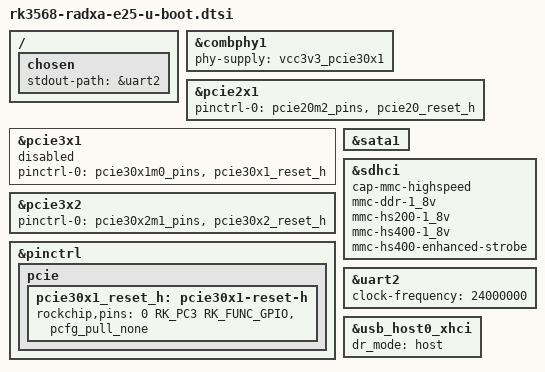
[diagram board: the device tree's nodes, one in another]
// SPDX-License-Identifier: GPL-2.0+

#include "rk356x-u-boot.dtsi"

/ {
	chosen {
		stdout-path = &uart2;
	};
};

&combphy1 {
	phy-supply = <&vcc3v3_pcie30x1>;
};

&pcie2x1 {
	pinctrl-0 = <&pcie20m2_pins &pcie20_reset_h>;
};

&pcie3x1 {
	pinctrl-0 = <&pcie30x1m0_pins &pcie30x1_reset_h>;
	/* May cause a sys freeze, disable for now */
	status = "disabled";
};

&pcie3x2 {
	pinctrl-0 = <&pcie30x2m1_pins &pcie30x2_reset_h>;
};

&pinctrl {
	pcie {
		pcie30x1_reset_h: pcie30x1-reset-h {
			rockchip,pins = <0 RK_PC3 RK_FUNC_GPIO &pcfg_pull_none>;
		};
	};
};

&sata1 {
	status = "okay";
};

&sdhci {
	cap-mmc-highspeed;
	mmc-ddr-1_8v;
	mmc-hs200-1_8v;
	mmc-hs400-1_8v;
	mmc-hs400-enhanced-strobe;
};

&uart2 {
	bootph-all;
	clock-frequency = <24000000>;
	status = "okay";
};

&usb_host0_xhci {
	dr_mode = "host";
};
